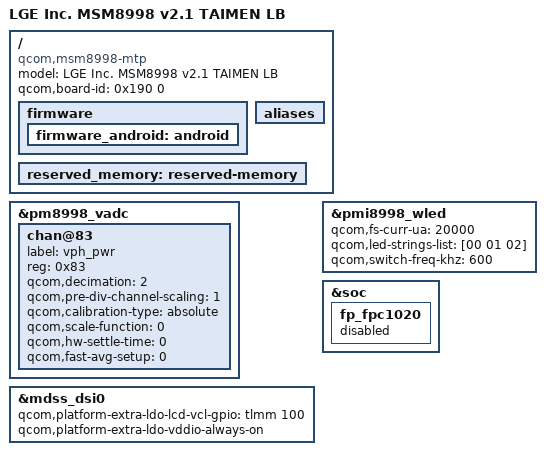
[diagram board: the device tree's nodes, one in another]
/* Copyright (c) 2017, The Linux Foundation. All rights reserved.
 *
 * This program is free software; you can redistribute it and/or modify
 * it under the terms of the GNU General Public License version 2 and
 * only version 2 as published by the Free Software Foundation.
 *
 * This program is distributed in the hope that it will be useful,
 * but WITHOUT ANY WARRANTY; without even the implied warranty of
 * MERCHANTABILITY or FITNESS FOR A PARTICULAR PURPOSE.  See the
 * GNU General Public License for more details.
 */

/dts-v1/;

/* WIP: Device tree overlay: SoC dtbo */
#include "../qcom/msm8998-v2.1.dtsi"
/ {
	compatible = "qcom,msm8998-mtp", "qcom,msm8998", "qcom,mtp";
	firmware {
		firmware_android: android {};
	};
};

/ {
	aliases: aliases {};
	reserved_memory: reserved-memory {};
};

/*
 * TODO: Device tree overlay:
 * below part is to be removed and the information will be
 * provided through DTB/DTBO partition dt_table_entry.
 */

/ {
	model = "LGE Inc. MSM8998 v2.1 TAIMEN LB";
	qcom,board-id = <0x190 0>;
};

/* WIP: Device tree overlay: overlay dtbo */
#include "msm8998-taimen.dtsi"

&pm8998_vadc {
	chan@83 {
		label = "vph_pwr";
		reg = <0x83>;
		qcom,decimation = <2>;
		qcom,pre-div-channel-scaling = <1>;
		qcom,calibration-type = "absolute";
		qcom,scale-function = <0>;
		qcom,hw-settle-time = <0>;
		qcom,fast-avg-setup = <0>;
	};
};

&mdss_dsi0 {
	/* LCD only */
	/delete-property/qcom,platform-extra-ldo-vpnl-gpio;
	qcom,platform-extra-ldo-lcd-vcl-gpio = <&tlmm 100 0>;
	qcom,platform-extra-ldo-vddio-always-on;
};

&pmi8998_wled {
	status = "okay";
	qcom,fs-curr-ua = <20000>;
	qcom,led-strings-list = [00 01 02];
	/* qcom,en-cabc; */
	qcom,switch-freq-khz = <600>;
};

&soc {
	fp_fpc1020 {
		status = "disabled";
	};
};
